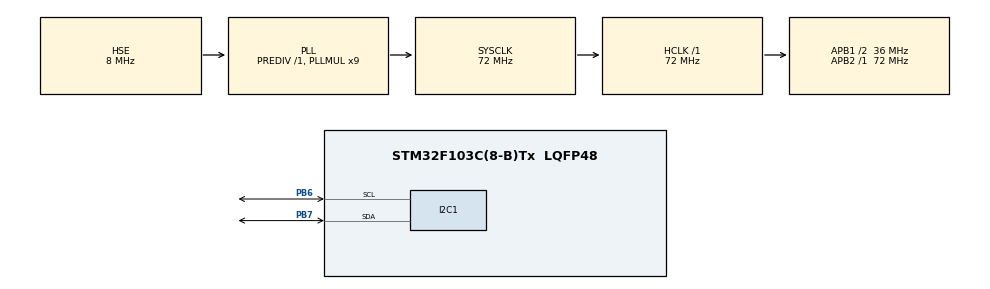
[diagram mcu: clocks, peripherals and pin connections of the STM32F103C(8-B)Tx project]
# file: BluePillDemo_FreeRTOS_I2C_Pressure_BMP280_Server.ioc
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FREERTOS.Queues01=pressureSensorQueue,1,8,1,Static,pressureSensorQueueBuffer,pressureSensorQueueControlBlock
FREERTOS.Tasks01=main,24,128,mainTask,Default,NULL,Static,mainBuffer,mainControlBlock;pressureSensor,8,128,pressureSensorTask,Default,NULL,Static,pressureSensorBuffer,pressureSensorControlBlock
Mcu.Family=STM32F1
Mcu.Name=STM32F103C(8-B)Tx
Mcu.Package=LQFP48
NVIC.PriorityGroup=NVIC_PRIORITYGROUP_4
NVIC.TIM1_UP_IRQn=true\:0\:0\:false\:false\:true\:false\:false\:true
NVIC.TimeBase=TIM1_UP_IRQn
NVIC.TimeBaseIP=TIM1
PA13.Mode=Serial_Wire
PA13.Signal=SYS_JTMS-SWDIO
PA14.Mode=Serial_Wire
PA14.Signal=SYS_JTCK-SWCLK
PB6.Mode=I2C
PB6.Signal=I2C1_SCL
PB7.Mode=I2C
PB7.Signal=I2C1_SDA
PC14-OSC32_IN.Mode=LSE-External-Oscillator
PC14-OSC32_IN.Signal=RCC_OSC32_IN
PC15-OSC32_OUT.Mode=LSE-External-Oscillator
PC15-OSC32_OUT.Signal=RCC_OSC32_OUT
PD0-OSC_IN.Mode=HSE-External-Oscillator
PD0-OSC_IN.Signal=RCC_OSC_IN
PD1-OSC_OUT.Mode=HSE-External-Oscillator
PD1-OSC_OUT.Signal=RCC_OSC_OUT
ProjectManager.HeapSize=0x200
ProjectManager.StackSize=0x400
ProjectManager.TargetToolchain=STM32CubeIDE
RCC.AHBFreq_Value=72000000
RCC.APB1CLKDivider=RCC_HCLK_DIV2
RCC.APB1Freq_Value=36000000
RCC.APB1TimFreq_Value=72000000
RCC.APB2Freq_Value=72000000
RCC.APB2TimFreq_Value=72000000
RCC.HCLKFreq_Value=72000000
RCC.PLLMUL=RCC_PLL_MUL9
RCC.PLLSourceVirtual=RCC_PLLSOURCE_HSE
RCC.SYSCLKFreq_VALUE=72000000
RCC.SYSCLKSource=RCC_SYSCLKSOURCE_PLLCLK
RCC.USBFreq_Value=72000000
VP_FREERTOS_VS_CMSIS_V2.Mode=CMSIS_V2
VP_SYS_VS_tim1.Mode=TIM1
board=custom

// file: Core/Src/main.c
/* USER CODE BEGIN Header */
/**
  ******************************************************************************
  * @file           : main.c
  * @brief          : Main program body
  ******************************************************************************
  * @attention
  *
  * <h2><center>&copy; Copyright (c) 2020 STMicroelectronics.
  * All rights reserved.</center></h2>
  *
  * This software component is licensed by ST under BSD 3-Clause license,
  * the "License"; You may not use this file except in compliance with the
  * License. You may obtain a copy of the License at:
  *                        opensource.org/licenses/BSD-3-Clause
  *
  ******************************************************************************
  */
/* USER CODE END Header */

#include "main.h"
#include "cmsis_os.h"

/* USER CODE BEGIN Includes */
#include "pressure_sensor.h"

/* USER CODE END Includes */

I2C_HandleTypeDef hi2c1;

typedef StaticTask_t osStaticThreadDef_t;
typedef StaticQueue_t osStaticMessageQDef_t;
osThreadId_t mainHandle;
uint32_t mainBuffer[ 128 ];
osStaticThreadDef_t mainControlBlock;
osThreadId_t pressureSensorHandle;
uint32_t pressureSensorBuffer[ 128 ];
osStaticThreadDef_t pressureSensorControlBlock;
osMessageQueueId_t pressureSensorQueueHandle;
uint8_t pressureSensorQueueBuffer[ 1 * 8 ];
osStaticMessageQDef_t pressureSensorQueueControlBlock;
/* USER CODE BEGIN PV */
osEventFlagsId_t modemTaskStartedEventHandle;
/* USER CODE END PV */

void SystemClock_Config(void);
static void MX_GPIO_Init(void);
static void MX_I2C1_Init(void);
void mainTask(void *argument);
void pressureSensorTask(void *argument);

int main(void)
{

  /* MCU Configuration--------------------------------------------------------*/

  /* Reset of all peripherals, Initializes the Flash interface and the Systick. */
  HAL_Init();

  /* Configure the system clock */
  SystemClock_Config();

  /* Initialize all configured peripherals */
  MX_GPIO_Init();
  MX_I2C1_Init();

  osKernelInitialize();

  /* USER CODE BEGIN RTOS_MUTEX */
  /* add mutexes, ... */
  modemTaskStartedEventHandle = osEventFlagsNew(NULL);
  /* USER CODE END RTOS_MUTEX */

  /* Create the queue(s) */
  /* definition and creation of pressureSensorQueue */
  const osMessageQueueAttr_t pressureSensorQueue_attributes = {
    .name = "pressureSensorQueue",
    .cb_mem = &pressureSensorQueueControlBlock,
    .cb_size = sizeof(pressureSensorQueueControlBlock),
    .mq_mem = &pressureSensorQueueBuffer,
    .mq_size = sizeof(pressureSensorQueueBuffer)
  };
  pressureSensorQueueHandle = osMessageQueueNew (1, 8, &pressureSensorQueue_attributes);

  /* Create the thread(s) */
  /* definition and creation of main */
  const osThreadAttr_t main_attributes = {
    .name = "main",
    .stack_mem = &mainBuffer[0],
    .stack_size = sizeof(mainBuffer),
    .cb_mem = &mainControlBlock,
    .cb_size = sizeof(mainControlBlock),
    .priority = (osPriority_t) osPriorityNormal,
  };
  mainHandle = osThreadNew(mainTask, NULL, &main_attributes);

  /* definition and creation of pressureSensor */
  const osThreadAttr_t pressureSensor_attributes = {
    .name = "pressureSensor",
    .stack_mem = &pressureSensorBuffer[0],
    .stack_size = sizeof(pressureSensorBuffer),
    .cb_mem = &pressureSensorControlBlock,
    .cb_size = sizeof(pressureSensorControlBlock),
    .priority = (osPriority_t) osPriorityLow,
  };
  pressureSensorHandle = osThreadNew(pressureSensorTask, NULL, &pressureSensor_attributes);

  /* Start scheduler */
  osKernelStart();

  /* We should never get here as control is now taken by the scheduler */

  /* Infinite loop */
  while (1)
  {

  }
}

void SystemClock_Config(void)
{
  RCC_OscInitTypeDef RCC_OscInitStruct = {0};
  RCC_ClkInitTypeDef RCC_ClkInitStruct = {0};

  /** Initializes the CPU, AHB and APB busses clocks
  */
  RCC_OscInitStruct.OscillatorType = RCC_OSCILLATORTYPE_HSE;
  RCC_OscInitStruct.HSEState = RCC_HSE_ON;
  RCC_OscInitStruct.HSEPredivValue = RCC_HSE_PREDIV_DIV1;
  RCC_OscInitStruct.HSIState = RCC_HSI_ON;
  RCC_OscInitStruct.PLL.PLLState = RCC_PLL_ON;
  RCC_OscInitStruct.PLL.PLLSource = RCC_PLLSOURCE_HSE;
  RCC_OscInitStruct.PLL.PLLMUL = RCC_PLL_MUL9;
  if (HAL_RCC_OscConfig(&RCC_OscInitStruct) != HAL_OK)
  {
    Error_Handler();
  }
  /** Initializes the CPU, AHB and APB busses clocks
  */
  RCC_ClkInitStruct.ClockType = RCC_CLOCKTYPE_HCLK|RCC_CLOCKTYPE_SYSCLK
                              |RCC_CLOCKTYPE_PCLK1|RCC_CLOCKTYPE_PCLK2;
  RCC_ClkInitStruct.SYSCLKSource = RCC_SYSCLKSOURCE_PLLCLK;
  RCC_ClkInitStruct.AHBCLKDivider = RCC_SYSCLK_DIV1;
  RCC_ClkInitStruct.APB1CLKDivider = RCC_HCLK_DIV2;
  RCC_ClkInitStruct.APB2CLKDivider = RCC_HCLK_DIV1;

  if (HAL_RCC_ClockConfig(&RCC_ClkInitStruct, FLASH_LATENCY_2) != HAL_OK)
  {
    Error_Handler();
  }
}

static void MX_I2C1_Init(void)
{

  hi2c1.Instance = I2C1;
  hi2c1.Init.ClockSpeed = 100000;
  hi2c1.Init.DutyCycle = I2C_DUTYCYCLE_2;
  hi2c1.Init.OwnAddress1 = 0;
  hi2c1.Init.AddressingMode = I2C_ADDRESSINGMODE_7BIT;
  hi2c1.Init.DualAddressMode = I2C_DUALADDRESS_DISABLE;
  hi2c1.Init.OwnAddress2 = 0;
  hi2c1.Init.GeneralCallMode = I2C_GENERALCALL_DISABLE;
  hi2c1.Init.NoStretchMode = I2C_NOSTRETCH_DISABLE;
  if (HAL_I2C_Init(&hi2c1) != HAL_OK)
  {
    Error_Handler();
  }

}

static void MX_GPIO_Init(void)
{

  /* GPIO Ports Clock Enable */
  __HAL_RCC_GPIOC_CLK_ENABLE();
  __HAL_RCC_GPIOD_CLK_ENABLE();
  __HAL_RCC_GPIOA_CLK_ENABLE();
  __HAL_RCC_GPIOB_CLK_ENABLE();

}

void mainTask(void *argument)
{
  /* USER CODE BEGIN 5 */
  pressure_sensor_data_t pressure_sensor_data;

  // wait for pressure sensor task to start
  osEventFlagsWait(modemTaskStartedEventHandle, 0x00000001U, osFlagsWaitAny, osWaitForever);

  /* Infinite loop */
  for(;;)
  {
    if (osMessageQueueGet(pressureSensorQueueHandle, &pressure_sensor_data, 0U, 0U) == osOK)
    {
    	float t = pressure_sensor_data.temperature;
    	float p = pressure_sensor_data.pressure;
    	(void)t;
    	(void)p;
    }

    osDelay(1000U);
  }
  /* USER CODE END 5 */
}

void pressureSensorTask(void *argument)
{
  /* USER CODE BEGIN pressureSensorTask */
  pressure_sensor_data_t pressure_sensor_data;

  pressure_sensor_init(&hi2c1);

  // signal main task that this thread has started
  osEventFlagsSet(modemTaskStartedEventHandle, 0x00000001U);

  /* Infinite loop */
  for (;;)
  {
	pressure_sensor_start_measurement();
    osDelay(500U);

    pressure_sensor_get_measurement(&pressure_sensor_data.pressure, &pressure_sensor_data.temperature);
    osMessageQueuePut(pressureSensorQueueHandle, &pressure_sensor_data, 0U, 0U);
    osDelay(500U);
  }
  /* USER CODE END pressureSensorTask */
}

void HAL_TIM_PeriodElapsedCallback(TIM_HandleTypeDef *htim)
{
  if (htim->Instance == TIM1) {
    HAL_IncTick();
  }
}

void Error_Handler(void)
{
}

/************************ (C) COPYRIGHT STMicroelectronics *****END OF FILE****/
